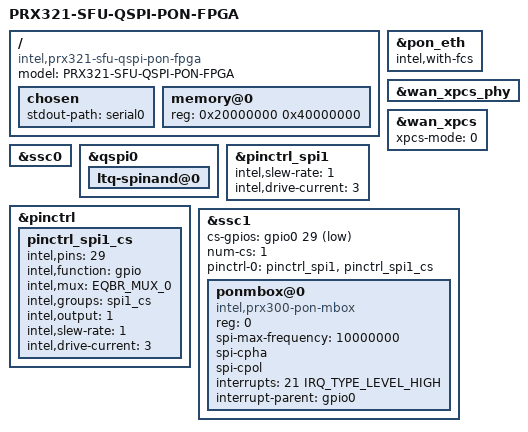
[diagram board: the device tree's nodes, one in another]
/dts-v1/;
#include <dt-bindings/gpio/gpio.h>
#include <dt-bindings/pinctrl/intel,equilibrium.h>
#include "prx321-sfu-12.dtsi"

/ {
	model = "PRX321-SFU-QSPI-PON-FPGA";
	compatible = "intel,prx321-sfu-qspi-pon-fpga", "intel,prx321-sfu-qspi-pon", "intel,prx321-sfu", "intel,prx300";

	chosen {
		stdout-path = "serial0";
	};

	memory@0 {
		device_type = "memory";
		reg = <0x20000000 0x40000000>; /* 1024 MB */
	};
};

&pon_eth {
	status = "okay";
	intel,with-fcs;
};

&wan_xpcs_phy {
	status = "okay";
};

&wan_xpcs {
	status = "okay";
	xpcs-mode = <0>; /* 0 - 10G_KR_MODE, 1 - 10G_XAUI_MODE, 2 - 1G_XAUI_MODE, 3 - 2P5G_GMII_MODE */
};

/* For voice enable the SPI driver needed for access to the on silicon VCODEC but prevent switching the pinmux to this SPI bus. On this design these pins are used for the QSPI bus. */
&ssc0 {
	status = "okay";
	/delete-property/ pinctrl-names;
	/delete-property/ pinctrl-0;
};

&qspi0 {
	status = "okay";
	ltq-spinand@0 {
		status = "okay";
	};
};

&pinctrl_spi1 {
	intel,slew-rate = <1>;
	intel,drive-current = <3>;
};

&pinctrl {
	pinctrl_spi1_cs: pinctrl_spi1_cs {
		intel,pins =  <29>;
		intel,function = "gpio";
		intel,mux = <EQBR_MUX_0>;
		intel,groups = "spi1_cs";
		intel,output = <1>;
		intel,slew-rate = <1>;
		intel,drive-current = <3>;
	};
};

&ssc1 {
	status = "okay";
	cs-gpios = <&gpio0 29 GPIO_ACTIVE_LOW>;
	num-cs = <1>;
	pinctrl-0 = <&pinctrl_spi1 &pinctrl_spi1_cs>;

	ponmbox@0 {
		compatible = "intel,prx300-pon-mbox";
		reg = <0>;
		spi-max-frequency = <10000000>;
		spi-cpha;
		spi-cpol;

		interrupts = <21 IRQ_TYPE_LEVEL_HIGH>;
		interrupt-parent = <&gpio0>;
	};
};
